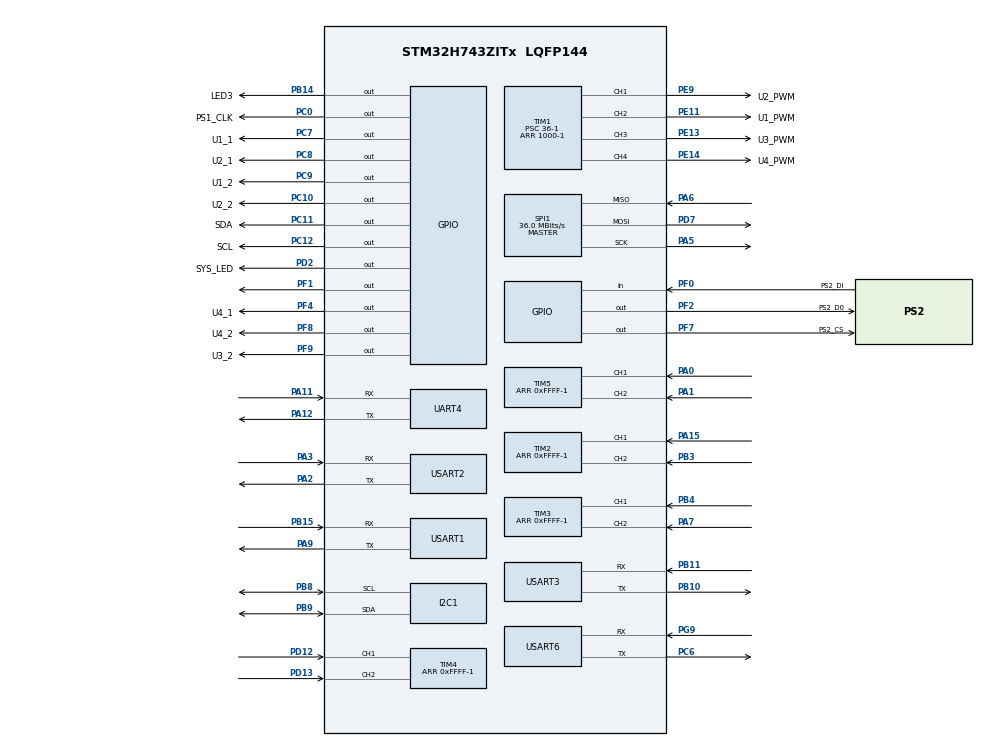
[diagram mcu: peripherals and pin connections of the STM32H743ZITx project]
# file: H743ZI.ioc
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Dma.I2C1_RX.1.Direction=DMA_PERIPH_TO_MEMORY
Dma.I2C1_RX.1.EventEnable=DISABLE
Dma.I2C1_RX.1.FIFOMode=DMA_FIFOMODE_DISABLE
Dma.I2C1_RX.1.Instance=DMA1_Stream0
Dma.I2C1_RX.1.MemDataAlignment=DMA_MDATAALIGN_BYTE
Dma.I2C1_RX.1.MemInc=DMA_MINC_ENABLE
Dma.I2C1_RX.1.Mode=DMA_NORMAL
Dma.I2C1_RX.1.PeriphDataAlignment=DMA_PDATAALIGN_BYTE
Dma.I2C1_RX.1.PeriphInc=DMA_PINC_DISABLE
Dma.I2C1_RX.1.Polarity=HAL_DMAMUX_REQ_GEN_RISING
Dma.I2C1_RX.1.Priority=DMA_PRIORITY_LOW
Dma.I2C1_RX.1.RequestNumber=1
Dma.I2C1_RX.1.SignalID=NONE
Dma.I2C1_RX.1.SyncEnable=DISABLE
Dma.I2C1_RX.1.SyncPolarity=HAL_DMAMUX_SYNC_NO_EVENT
Dma.I2C1_RX.1.SyncRequestNumber=1
Dma.I2C1_RX.1.SyncSignalID=NONE
Dma.I2C1_TX.2.Direction=DMA_MEMORY_TO_PERIPH
Dma.I2C1_TX.2.EventEnable=DISABLE
Dma.I2C1_TX.2.FIFOMode=DMA_FIFOMODE_DISABLE
Dma.I2C1_TX.2.Instance=DMA1_Stream2
Dma.I2C1_TX.2.MemDataAlignment=DMA_MDATAALIGN_BYTE
Dma.I2C1_TX.2.MemInc=DMA_MINC_ENABLE
Dma.I2C1_TX.2.Mode=DMA_NORMAL
Dma.I2C1_TX.2.PeriphDataAlignment=DMA_PDATAALIGN_BYTE
Dma.I2C1_TX.2.PeriphInc=DMA_PINC_DISABLE
Dma.I2C1_TX.2.Polarity=HAL_DMAMUX_REQ_GEN_RISING
Dma.I2C1_TX.2.Priority=DMA_PRIORITY_LOW
Dma.I2C1_TX.2.RequestNumber=1
Dma.I2C1_TX.2.SignalID=NONE
Dma.I2C1_TX.2.SyncEnable=DISABLE
Dma.I2C1_TX.2.SyncPolarity=HAL_DMAMUX_SYNC_NO_EVENT
Dma.I2C1_TX.2.SyncRequestNumber=1
Dma.I2C1_TX.2.SyncSignalID=NONE
Dma.Request0=UART4_TX
Dma.Request1=I2C1_RX
Dma.Request2=I2C1_TX
Dma.Request3=USART1_RX
Dma.Request4=USART1_TX
Dma.Request5=USART6_RX
Dma.Request6=USART6_TX
Dma.Request7=USART3_RX
Dma.Request8=USART3_TX
Dma.UART4_TX.0.Direction=DMA_MEMORY_TO_PERIPH
Dma.UART4_TX.0.EventEnable=DISABLE
Dma.UART4_TX.0.FIFOMode=DMA_FIFOMODE_DISABLE
Dma.UART4_TX.0.Instance=DMA1_Stream1
Dma.UART4_TX.0.MemDataAlignment=DMA_MDATAALIGN_BYTE
Dma.UART4_TX.0.MemInc=DMA_MINC_ENABLE
Dma.UART4_TX.0.Mode=DMA_NORMAL
Dma.UART4_TX.0.PeriphDataAlignment=DMA_PDATAALIGN_BYTE
Dma.UART4_TX.0.PeriphInc=DMA_PINC_DISABLE
Dma.UART4_TX.0.Polarity=HAL_DMAMUX_REQ_GEN_RISING
Dma.UART4_TX.0.Priority=DMA_PRIORITY_LOW
Dma.UART4_TX.0.RequestNumber=1
Dma.UART4_TX.0.SignalID=NONE
Dma.UART4_TX.0.SyncEnable=DISABLE
Dma.UART4_TX.0.SyncPolarity=HAL_DMAMUX_SYNC_NO_EVENT
Dma.UART4_TX.0.SyncRequestNumber=1
Dma.UART4_TX.0.SyncSignalID=NONE
Dma.USART1_RX.3.Direction=DMA_PERIPH_TO_MEMORY
Dma.USART1_RX.3.EventEnable=DISABLE
Dma.USART1_RX.3.FIFOMode=DMA_FIFOMODE_DISABLE
Dma.USART1_RX.3.Instance=DMA1_Stream4
Dma.USART1_RX.3.MemDataAlignment=DMA_MDATAALIGN_BYTE
Dma.USART1_RX.3.MemInc=DMA_MINC_ENABLE
Dma.USART1_RX.3.Mode=DMA_NORMAL
Dma.USART1_RX.3.PeriphDataAlignment=DMA_PDATAALIGN_BYTE
Dma.USART1_RX.3.PeriphInc=DMA_PINC_DISABLE
Dma.USART1_RX.3.Polarity=HAL_DMAMUX_REQ_GEN_RISING
Dma.USART1_RX.3.Priority=DMA_PRIORITY_LOW
Dma.USART1_RX.3.RequestNumber=1
Dma.USART1_RX.3.SignalID=NONE
Dma.USART1_RX.3.SyncEnable=DISABLE
Dma.USART1_RX.3.SyncPolarity=HAL_DMAMUX_SYNC_NO_EVENT
Dma.USART1_RX.3.SyncRequestNumber=1
Dma.USART1_RX.3.SyncSignalID=NONE
Dma.USART1_TX.4.Direction=DMA_MEMORY_TO_PERIPH
Dma.USART1_TX.4.EventEnable=DISABLE
Dma.USART1_TX.4.FIFOMode=DMA_FIFOMODE_DISABLE
Dma.USART1_TX.4.Instance=DMA1_Stream5
Dma.USART1_TX.4.MemDataAlignment=DMA_MDATAALIGN_BYTE
Dma.USART1_TX.4.MemInc=DMA_MINC_ENABLE
Dma.USART1_TX.4.Mode=DMA_NORMAL
Dma.USART1_TX.4.PeriphDataAlignment=DMA_PDATAALIGN_BYTE
Dma.USART1_TX.4.PeriphInc=DMA_PINC_DISABLE
Dma.USART1_TX.4.Polarity=HAL_DMAMUX_REQ_GEN_RISING
Dma.USART1_TX.4.Priority=DMA_PRIORITY_LOW
Dma.USART1_TX.4.RequestNumber=1
Dma.USART1_TX.4.SignalID=NONE
Dma.USART1_TX.4.SyncEnable=DISABLE
Dma.USART1_TX.4.SyncPolarity=HAL_DMAMUX_SYNC_NO_EVENT
Dma.USART1_TX.4.SyncRequestNumber=1
Dma.USART1_TX.4.SyncSignalID=NONE
Dma.USART3_RX.7.Direction=DMA_PERIPH_TO_MEMORY
Dma.USART3_RX.7.EventEnable=DISABLE
Dma.USART3_RX.7.FIFOMode=DMA_FIFOMODE_DISABLE
Dma.USART3_RX.7.Instance=DMA1_Stream3
Dma.USART3_RX.7.MemDataAlignment=DMA_MDATAALIGN_BYTE
Dma.USART3_RX.7.MemInc=DMA_MINC_ENABLE
Dma.USART3_RX.7.Mode=DMA_CIRCULAR
Dma.USART3_RX.7.PeriphDataAlignment=DMA_PDATAALIGN_BYTE
Dma.USART3_RX.7.PeriphInc=DMA_PINC_DISABLE
Dma.USART3_RX.7.Polarity=HAL_DMAMUX_REQ_GEN_RISING
Dma.USART3_RX.7.Priority=DMA_PRIORITY_LOW
Dma.USART3_RX.7.RequestNumber=1
Dma.USART3_RX.7.SignalID=NONE
Dma.USART3_RX.7.SyncEnable=DISABLE
Dma.USART3_RX.7.SyncPolarity=HAL_DMAMUX_SYNC_NO_EVENT
Dma.USART3_RX.7.SyncRequestNumber=1
Dma.USART3_RX.7.SyncSignalID=NONE
Dma.USART3_TX.8.Direction=DMA_MEMORY_TO_PERIPH
Dma.USART3_TX.8.EventEnable=DISABLE
Dma.USART3_TX.8.FIFOMode=DMA_FIFOMODE_DISABLE
Dma.USART3_TX.8.Instance=DMA2_Stream0
Dma.USART3_TX.8.MemDataAlignment=DMA_MDATAALIGN_BYTE
Dma.USART3_TX.8.MemInc=DMA_MINC_ENABLE
Dma.USART3_TX.8.Mode=DMA_CIRCULAR
Dma.USART3_TX.8.PeriphDataAlignment=DMA_PDATAALIGN_BYTE
Dma.USART3_TX.8.PeriphInc=DMA_PINC_DISABLE
Dma.USART3_TX.8.Polarity=HAL_DMAMUX_REQ_GEN_RISING
Dma.USART3_TX.8.Priority=DMA_PRIORITY_LOW
Dma.USART3_TX.8.RequestNumber=1
Dma.USART3_TX.8.SignalID=NONE
Dma.USART3_TX.8.SyncEnable=DISABLE
Dma.USART3_TX.8.SyncPolarity=HAL_DMAMUX_SYNC_NO_EVENT
Dma.USART3_TX.8.SyncRequestNumber=1
Dma.USART3_TX.8.SyncSignalID=NONE
Dma.USART6_RX.5.Direction=DMA_PERIPH_TO_MEMORY
Dma.USART6_RX.5.EventEnable=DISABLE
Dma.USART6_RX.5.FIFOMode=DMA_FIFOMODE_DISABLE
Dma.USART6_RX.5.Instance=DMA1_Stream6
Dma.USART6_RX.5.MemDataAlignment=DMA_MDATAALIGN_BYTE
Dma.USART6_RX.5.MemInc=DMA_MINC_ENABLE
Dma.USART6_RX.5.Mode=DMA_CIRCULAR
Dma.USART6_RX.5.PeriphDataAlignment=DMA_PDATAALIGN_BYTE
Dma.USART6_RX.5.PeriphInc=DMA_PINC_DISABLE
Dma.USART6_RX.5.Polarity=HAL_DMAMUX_REQ_GEN_RISING
Dma.USART6_RX.5.Priority=DMA_PRIORITY_LOW
Dma.USART6_RX.5.RequestNumber=1
Dma.USART6_RX.5.SignalID=NONE
Dma.USART6_RX.5.SyncEnable=DISABLE
Dma.USART6_RX.5.SyncPolarity=HAL_DMAMUX_SYNC_NO_EVENT
Dma.USART6_RX.5.SyncRequestNumber=1
Dma.USART6_RX.5.SyncSignalID=NONE
Dma.USART6_TX.6.Direction=DMA_MEMORY_TO_PERIPH
Dma.USART6_TX.6.EventEnable=DISABLE
Dma.USART6_TX.6.FIFOMode=DMA_FIFOMODE_DISABLE
Dma.USART6_TX.6.Instance=DMA1_Stream7
Dma.USART6_TX.6.MemDataAlignment=DMA_MDATAALIGN_BYTE
Dma.USART6_TX.6.MemInc=DMA_MINC_ENABLE
Dma.USART6_TX.6.Mode=DMA_CIRCULAR
Dma.USART6_TX.6.PeriphDataAlignment=DMA_PDATAALIGN_BYTE
Dma.USART6_TX.6.PeriphInc=DMA_PINC_DISABLE
Dma.USART6_TX.6.Polarity=HAL_DMAMUX_REQ_GEN_RISING
Dma.USART6_TX.6.Priority=DMA_PRIORITY_LOW
Dma.USART6_TX.6.RequestNumber=1
Dma.USART6_TX.6.SignalID=NONE
Dma.USART6_TX.6.SyncEnable=DISABLE
Dma.USART6_TX.6.SyncPolarity=HAL_DMAMUX_SYNC_NO_EVENT
Dma.USART6_TX.6.SyncRequestNumber=1
Dma.USART6_TX.6.SyncSignalID=NONE
I2C1.Timing=0x00808CD2
IWDG1.Prescaler=IWDG_PRESCALER_64
IWDG1.Reload=1000
Mcu.Family=STM32H7
Mcu.Name=STM32H743ZITx
Mcu.Package=LQFP144
NVIC.DMA1_Stream0_IRQn=true\:0\:0\:false\:false\:true\:false\:true
NVIC.DMA1_Stream1_IRQn=true\:0\:0\:false\:false\:true\:false\:true
NVIC.DMA1_Stream2_IRQn=true\:0\:0\:false\:false\:true\:false\:true
NVIC.DMA1_Stream3_IRQn=true\:0\:0\:false\:false\:true\:false\:true
NVIC.DMA1_Stream4_IRQn=true\:0\:0\:false\:false\:true\:false\:true
NVIC.DMA1_Stream5_IRQn=true\:0\:0\:false\:false\:true\:false\:true
NVIC.DMA1_Stream6_IRQn=true\:0\:0\:false\:false\:true\:false\:true
NVIC.DMA1_Stream7_IRQn=true\:0\:0\:false\:false\:true\:false\:true
NVIC.DMA2_Stream0_IRQn=true\:0\:0\:false\:false\:true\:false\:true
NVIC.I2C1_ER_IRQn=true\:0\:0\:false\:false\:true\:true\:true
NVIC.I2C1_EV_IRQn=true\:0\:0\:false\:false\:true\:true\:true
NVIC.PriorityGroup=NVIC_PRIORITYGROUP_4
NVIC.TIM6_DAC_IRQn=true\:0\:0\:false\:false\:true\:true\:true
NVIC.TIM7_IRQn=true\:0\:0\:false\:false\:true\:false\:true
NVIC.TimeBase=TIM7_IRQn
NVIC.TimeBaseIP=TIM7
NVIC.UART4_IRQn=true\:0\:0\:false\:false\:true\:true\:true
NVIC.USART1_IRQn=true\:0\:0\:false\:false\:true\:true\:true
NVIC.USART2_IRQn=true\:0\:0\:false\:false\:true\:true\:true
NVIC.USART3_IRQn=true\:0\:0\:false\:false\:true\:true\:true
NVIC.USART6_IRQn=true\:0\:0\:false\:false\:true\:true\:true
PA0.Signal=S_TIM5_CH1
PA1.Signal=S_TIM5_CH2
PA11.Mode=Asynchronous
PA11.Signal=UART4_RX
PA12.Mode=Asynchronous
PA12.Signal=UART4_TX
PA13\ (JTMS/SWDIO).Mode=Trace_Synchro_4bits_SW
PA13\ (JTMS/SWDIO).Signal=DEBUG_JTMS-SWDIO
PA14\ (JTCK/SWCLK).Mode=Trace_Synchro_4bits_SW
PA14\ (JTCK/SWCLK).Signal=DEBUG_JTCK-SWCLK
PA15\ (JTDI).Signal=S_TIM2_CH1
PA2.Mode=Asynchronous
PA2.Signal=USART2_TX
PA3.Mode=Asynchronous
PA3.Signal=USART2_RX
PA5.Mode=Full_Duplex_Master
PA5.Signal=SPI1_SCK
PA6.Mode=Full_Duplex_Master
PA6.Signal=SPI1_MISO
PA7.Signal=S_TIM3_CH2
PA9.Mode=Asynchronous
PA9.Signal=USART1_TX
PB10.Mode=Asynchronous
PB10.Signal=USART3_TX
PB11.Mode=Asynchronous
PB11.Signal=USART3_RX
PB14.GPIO_Label=LED3
PB14.Signal=GPIO_Output
PB15.Mode=Asynchronous
PB15.Signal=USART1_RX
PB3\ (JTDO/TRACESWO).Signal=S_TIM2_CH2
PB4\ (NJTRST).Signal=S_TIM3_CH1
PB8.Mode=I2C
PB8.Signal=I2C1_SCL
PB9.Mode=I2C
PB9.Signal=I2C1_SDA
PC0.GPIO_Label=PS1_CLK
PC0.Signal=GPIO_Output
PC10.GPIO_Label=U2_2
PC10.Signal=GPIO_Output
PC11.GPIO_Label=SDA
PC11.GPIO_ModeDefaultOutputPP=GPIO_MODE_OUTPUT_OD
PC11.Signal=GPIO_Output
PC12.GPIO_Label=SCL
PC12.GPIO_ModeDefaultOutputPP=GPIO_MODE_OUTPUT_OD
PC12.Signal=GPIO_Output
PC14-OSC32_IN\ (OSC32_IN).Mode=LSE-External-Oscillator
PC14-OSC32_IN\ (OSC32_IN).Signal=RCC_OSC32_IN
PC15-OSC32_OUT\ (OSC32_OUT).Mode=LSE-External-Oscillator
PC15-OSC32_OUT\ (OSC32_OUT).Signal=RCC_OSC32_OUT
PC6.Mode=Asynchronous
PC6.Signal=USART6_TX
PC7.GPIO_Label=U1_1
PC7.Signal=GPIO_Output
PC8.GPIO_Label=U2_1
PC8.Signal=GPIO_Output
PC9.GPIO_Label=U1_2
PC9.Signal=GPIO_Output
PD12.Signal=S_TIM4_CH1
PD13.Signal=S_TIM4_CH2
PD2.GPIO_Label=SYS_LED
PD2.Signal=GPIO_Output
PD7.Mode=Full_Duplex_Master
PD7.Signal=SPI1_MOSI
PE11.GPIO_Label=U1_PWM
PE11.Signal=S_TIM1_CH2
PE13.GPIO_Label=U3_PWM
PE13.Signal=S_TIM1_CH3
PE14.GPIO_Label=U4_PWM
PE14.Signal=S_TIM1_CH4
PE2.Mode=Trace_Synchro_4bits_SW
PE2.Signal=DEBUG_TRACECLK
PE3.Mode=Trace_Synchro_4bits_SW
PE3.Signal=DEBUG_TRACED0
PE4.Mode=Trace_Synchro_4bits_SW
PE4.Signal=DEBUG_TRACED1
PE5.Mode=Trace_Synchro_4bits_SW
PE5.Signal=DEBUG_TRACED2
PE6.Mode=Trace_Synchro_4bits_SW
PE6.Signal=DEBUG_TRACED3
PE9.GPIO_Label=U2_PWM
PE9.Signal=S_TIM1_CH1
PF0.GPIO_Label=PS2_DI
PF0.GPIO_PuPd=GPIO_PULLDOWN
PF0.Signal=GPIO_Input
PF1.Signal=GPIO_Output
PF2.GPIO_Label=PS2_D0
PF2.Signal=GPIO_Output
PF4.GPIO_Label=U4_1
PF4.Signal=GPIO_Output
PF7.GPIO_Label=PS2_CS
PF7.Signal=GPIO_Output
PF8.GPIO_Label=U4_2
PF8.Signal=GPIO_Output
PF9.GPIO_Label=U3_2
PF9.Signal=GPIO_Output
PG9.Mode=Asynchronous
PG9.Signal=USART6_RX
PH0-OSC_IN\ (PH0).Mode=HSE-External-Oscillator
PH0-OSC_IN\ (PH0).Signal=RCC_OSC_IN
PH1-OSC_OUT\ (PH1).Mode=HSE-External-Oscillator
PH1-OSC_OUT\ (PH1).Signal=RCC_OSC_OUT
ProjectManager.HeapSize=0x200
ProjectManager.StackSize=0x400
ProjectManager.TargetToolchain=MDK-ARM V5
RCC.ADCFreq_Value=129000000
RCC.APB1Freq_Value=36000000
RCC.APB2Freq_Value=36000000
RCC.APB3Freq_Value=36000000
RCC.APB4Freq_Value=36000000
RCC.CortexFreq_Value=72000000
RCC.D1CPRE=RCC_SYSCLK_DIV2
RCC.DIVM1=4
RCC.DIVN1=18
RCC.HCLKFreq_Value=36000000
RCC.HPRE=RCC_HCLK_DIV2
RCC.PLL2FRACN=0
RCC.PLL3FRACN=0
RCC.PLLFRACN=0
RCC.SYSCLKFreq_VALUE=144000000
RCC.SYSCLKSource=RCC_SYSCLKSOURCE_PLLCLK
RCC.USBFreq_Value=144000000
SH.S_TIM1_CH1.0=TIM1_CH1,PWM Generation1 CH1
SH.S_TIM1_CH2.0=TIM1_CH2,PWM Generation2 CH2
SH.S_TIM1_CH3.0=TIM1_CH3,Output Compare3 CH3
SH.S_TIM1_CH4.0=TIM1_CH4,Output Compare4 CH4
SH.S_TIM2_CH1.0=TIM2_CH1,Encoder_Interface
SH.S_TIM2_CH2.0=TIM2_CH2,Encoder_Interface
SH.S_TIM3_CH1.0=TIM3_CH1,Encoder_Interface
SH.S_TIM3_CH2.0=TIM3_CH2,Encoder_Interface
SH.S_TIM4_CH1.0=TIM4_CH1,Encoder_Interface
SH.S_TIM4_CH2.0=TIM4_CH2,Encoder_Interface
SH.S_TIM5_CH1.0=TIM5_CH1,Encoder_Interface
SH.S_TIM5_CH2.0=TIM5_CH2,Encoder_Interface
SPI1.BaudRatePrescaler=SPI_BAUDRATEPRESCALER_4
SPI1.CalculateBaudRate=36.0 MBits/s
SPI1.Direction=SPI_DIRECTION_2LINES
SPI1.Mode=SPI_MODE_MASTER
SPI1.VirtualType=VM_MASTER
TIM1.Channel-Output\ Compare3\ CH3=TIM_CHANNEL_3
TIM1.Channel-Output\ Compare4\ CH4=TIM_CHANNEL_4
TIM1.Channel-PWM\ Generation1\ CH1=TIM_CHANNEL_1
TIM1.Channel-PWM\ Generation2\ CH2=TIM_CHANNEL_2
TIM1.ClockDivision=TIM_CLOCKDIVISION_DIV4
TIM1.Period=1000-1
TIM1.Prescaler=36-1
TIM2.EncoderMode=TIM_ENCODERMODE_TI12
TIM2.Period=0xFFFF-1
TIM3.Period=0xFFFF-1
TIM4.Period=0xFFFF-1
TIM5.Period=0xFFFF-1
TIM6.Period=10000-1
TIM6.Prescaler=144-1
USART1.VirtualMode-Asynchronous=VM_ASYNC
USART2.VirtualMode-Asynchronous=VM_ASYNC
USART3.VirtualMode-Asynchronous=VM_ASYNC
USART6.VirtualMode-Asynchronous=VM_ASYNC
VP_IWDG1_VS_IWDG.Mode=IWDG_Activate
VP_SYS_VS_tim7.Mode=TIM7
VP_TIM1_VS_ClockSourceINT.Mode=Internal
VP_TIM6_VS_ClockSourceINT.Mode=Enable_Timer
board=custom

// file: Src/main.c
/* USER CODE BEGIN Header */
/**
  ******************************************************************************
  * @file           : main.c
  * @brief          : Main program body
  ******************************************************************************
  * @attention
  *
  * <h2><center>&copy; Copyright (c) 2019 STMicroelectronics.
  * All rights reserved.</center></h2>
  *
  * This software component is licensed by ST under BSD 3-Clause license,
  * the "License"; You may not use this file except in compliance with the
  * License. You may obtain a copy of the License at:
  *                        opensource.org/licenses/BSD-3-Clause
  *
  ******************************************************************************
  */
/* USER CODE END Header */

#include "main.h"
#include "dma.h"
#include "i2c.h"
#include "iwdg.h"
#include "spi.h"
#include "tim.h"
#include "usart.h"
#include "gpio.h"

/* USER CODE BEGIN Includes */
#include "user_system.h"
/* USER CODE END Includes */

void SystemClock_Config(void);

int main(void)
{

  /* MCU Configuration--------------------------------------------------------*/

  /* Reset of all peripherals, Initializes the Flash interface and the Systick. */
  HAL_Init();

  /* Configure the system clock */
  SystemClock_Config();

  /* Initialize all configured peripherals */
  MX_GPIO_Init();
  MX_DMA_Init();
  MX_I2C1_Init();
  MX_IWDG1_Init();
  MX_SPI1_Init();
  MX_TIM1_Init();
  MX_TIM2_Init();
  MX_TIM3_Init();
  MX_TIM4_Init();
  MX_TIM5_Init();
  MX_TIM6_Init();
  MX_UART4_Init();
  MX_USART2_UART_Init();
  MX_USART3_UART_Init();
  MX_USART1_UART_Init();
  MX_USART6_UART_Init();
  /* USER CODE BEGIN 2 */
	user_system_init();
	user_system_thread_0();
  /* USER CODE END 2 */

  /* Infinite loop */
  while (1)
  {

  }
}

void SystemClock_Config(void)
{
  RCC_OscInitTypeDef RCC_OscInitStruct = {0};
  RCC_ClkInitTypeDef RCC_ClkInitStruct = {0};
  RCC_PeriphCLKInitTypeDef PeriphClkInitStruct = {0};

  /** Supply configuration update enable
  */
  HAL_PWREx_ConfigSupply(PWR_LDO_SUPPLY);
  /** Configure the main internal regulator output voltage
  */
  __HAL_PWR_VOLTAGESCALING_CONFIG(PWR_REGULATOR_VOLTAGE_SCALE3);

  while(!__HAL_PWR_GET_FLAG(PWR_FLAG_VOSRDY)) {}
  /** Initializes the CPU, AHB and APB busses clocks
  */
  RCC_OscInitStruct.OscillatorType = RCC_OSCILLATORTYPE_HSI|RCC_OSCILLATORTYPE_LSI;
  RCC_OscInitStruct.HSIState = RCC_HSI_DIV1;
  RCC_OscInitStruct.HSICalibrationValue = RCC_HSICALIBRATION_DEFAULT;
  RCC_OscInitStruct.LSIState = RCC_LSI_ON;
  RCC_OscInitStruct.PLL.PLLState = RCC_PLL_ON;
  RCC_OscInitStruct.PLL.PLLSource = RCC_PLLSOURCE_HSI;
  RCC_OscInitStruct.PLL.PLLM = 4;
  RCC_OscInitStruct.PLL.PLLN = 18;
  RCC_OscInitStruct.PLL.PLLP = 2;
  RCC_OscInitStruct.PLL.PLLQ = 2;
  RCC_OscInitStruct.PLL.PLLR = 2;
  RCC_OscInitStruct.PLL.PLLRGE = RCC_PLL1VCIRANGE_3;
  RCC_OscInitStruct.PLL.PLLVCOSEL = RCC_PLL1VCOWIDE;
  RCC_OscInitStruct.PLL.PLLFRACN = 0;
  if (HAL_RCC_OscConfig(&RCC_OscInitStruct) != HAL_OK)
  {
    Error_Handler();
  }
  /** Initializes the CPU, AHB and APB busses clocks
  */
  RCC_ClkInitStruct.ClockType = RCC_CLOCKTYPE_HCLK|RCC_CLOCKTYPE_SYSCLK
                              |RCC_CLOCKTYPE_PCLK1|RCC_CLOCKTYPE_PCLK2
                              |RCC_CLOCKTYPE_D3PCLK1|RCC_CLOCKTYPE_D1PCLK1;
  RCC_ClkInitStruct.SYSCLKSource = RCC_SYSCLKSOURCE_PLLCLK;
  RCC_ClkInitStruct.SYSCLKDivider = RCC_SYSCLK_DIV2;
  RCC_ClkInitStruct.AHBCLKDivider = RCC_HCLK_DIV2;
  RCC_ClkInitStruct.APB3CLKDivider = RCC_APB3_DIV1;
  RCC_ClkInitStruct.APB1CLKDivider = RCC_APB1_DIV1;
  RCC_ClkInitStruct.APB2CLKDivider = RCC_APB2_DIV1;
  RCC_ClkInitStruct.APB4CLKDivider = RCC_APB4_DIV1;

  if (HAL_RCC_ClockConfig(&RCC_ClkInitStruct, FLASH_LATENCY_0) != HAL_OK)
  {
    Error_Handler();
  }
  PeriphClkInitStruct.PeriphClockSelection = RCC_PERIPHCLK_USART3|RCC_PERIPHCLK_USART2
                              |RCC_PERIPHCLK_UART4|RCC_PERIPHCLK_USART6
                              |RCC_PERIPHCLK_USART1|RCC_PERIPHCLK_SPI1
                              |RCC_PERIPHCLK_I2C1;
  PeriphClkInitStruct.Spi123ClockSelection = RCC_SPI123CLKSOURCE_PLL;
  PeriphClkInitStruct.Usart234578ClockSelection = RCC_USART234578CLKSOURCE_D2PCLK1;
  PeriphClkInitStruct.Usart16ClockSelection = RCC_USART16CLKSOURCE_D2PCLK2;
  PeriphClkInitStruct.I2c123ClockSelection = RCC_I2C123CLKSOURCE_D2PCLK1;
  if (HAL_RCCEx_PeriphCLKConfig(&PeriphClkInitStruct) != HAL_OK)
  {
    Error_Handler();
  }
}

void HAL_TIM_PeriodElapsedCallback(TIM_HandleTypeDef *htim)
{
  if (htim->Instance == TIM7) {
    HAL_IncTick();
  }
  /* USER CODE BEGIN Callback 1 */
  if(htim == &htim6){
		if(cmd_flag >= 10){
			cmd_liner_vel_x = cmd_liner_vel_y = cmd_angular_rad_z = 0;
		}
		else{
			cmd_flag++;
		}
	}
  /* USER CODE END Callback 1 */
}

void Error_Handler(void)
{
}

/************************ (C) COPYRIGHT STMicroelectronics *****END OF FILE****/
